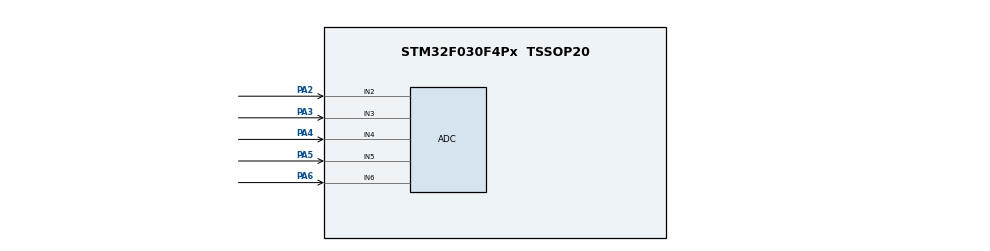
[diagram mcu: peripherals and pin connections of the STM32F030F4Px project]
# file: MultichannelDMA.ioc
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ADC.ClockPrescaler=ADC_CLOCK_SYNC_PCLK_DIV2
ADC.ContinuousConvMode=ENABLE
ADC.DMAContinuousRequests=ENABLE
ADC.Overrun=ADC_OVR_DATA_OVERWRITTEN
ADC.SamplingTime=ADC_SAMPLETIME_71CYCLES_5
Dma.ADC.0.Direction=DMA_PERIPH_TO_MEMORY
Dma.ADC.0.Instance=DMA1_Channel1
Dma.ADC.0.MemDataAlignment=DMA_MDATAALIGN_WORD
Dma.ADC.0.MemInc=DMA_MINC_ENABLE
Dma.ADC.0.Mode=DMA_CIRCULAR
Dma.ADC.0.PeriphDataAlignment=DMA_PDATAALIGN_WORD
Dma.ADC.0.PeriphInc=DMA_PINC_DISABLE
Dma.ADC.0.Priority=DMA_PRIORITY_LOW
Dma.Request0=ADC
Mcu.Family=STM32F0
Mcu.Name=STM32F030F4Px
Mcu.Package=TSSOP20
NVIC.ADC1_IRQn=true\:0\:0\:false\:false\:true\:true\:true
NVIC.DMA1_Channel1_IRQn=true\:0\:0\:false\:false\:true\:false\:true
PA2.Mode=IN2
PA2.Signal=ADC_IN2
PA3.Mode=IN3
PA3.Signal=ADC_IN3
PA4.Mode=IN4
PA4.Signal=ADC_IN4
PA5.Mode=IN5
PA5.Signal=ADC_IN5
PA6.Mode=IN6
PA6.Signal=ADC_IN6
ProjectManager.HeapSize=0x200
ProjectManager.StackSize=0x400
ProjectManager.TargetToolchain=SW4STM32
board=custom

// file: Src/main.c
/* USER CODE BEGIN Header */
/**
  ******************************************************************************
  * @file           : main.c
  * @brief          : Main program body
  ******************************************************************************
  * @attention
  *
  * <h2><center>&copy; Copyright (c) 2019 STMicroelectronics.
  * All rights reserved.</center></h2>
  *
  * This software component is licensed by ST under BSD 3-Clause license,
  * the "License"; You may not use this file except in compliance with the
  * License. You may obtain a copy of the License at:
  *                        opensource.org/licenses/BSD-3-Clause
  *
  ******************************************************************************
  */
/* USER CODE END Header */

#include "main.h"

ADC_HandleTypeDef hadc;
DMA_HandleTypeDef hdma_adc;

/* USER CODE BEGIN PV */
int data[5];
/* USER CODE END PV */

void SystemClock_Config(void);
static void MX_GPIO_Init(void);
static void MX_DMA_Init(void);
static void MX_ADC_Init(void);

int main(void)
{

  /* MCU Configuration--------------------------------------------------------*/

  /* Reset of all peripherals, Initializes the Flash interface and the Systick. */
  HAL_Init();

  /* Configure the system clock */
  SystemClock_Config();

  /* Initialize all configured peripherals */
  MX_GPIO_Init();
  MX_DMA_Init();
  MX_ADC_Init();
  /* USER CODE BEGIN 2 */

  if(HAL_ADCEx_Calibration_Start(&hadc) != HAL_OK){
	  Error_Handler();
  }

  if(HAL_ADC_Start_DMA(&hadc, data, 5) != HAL_OK){
	  Error_Handler();
  }

  /* USER CODE END 2 */

  /* Infinite loop */
  /* USER CODE BEGIN WHILE */
  while (1)
  {

	  HAL_Delay(1);
    /* USER CODE END WHILE */

  }
}

void SystemClock_Config(void)
{
  RCC_OscInitTypeDef RCC_OscInitStruct = {0};
  RCC_ClkInitTypeDef RCC_ClkInitStruct = {0};

  /** Initializes the CPU, AHB and APB busses clocks
  */
  RCC_OscInitStruct.OscillatorType = RCC_OSCILLATORTYPE_HSI;
  RCC_OscInitStruct.HSIState = RCC_HSI_ON;
  RCC_OscInitStruct.HSICalibrationValue = RCC_HSICALIBRATION_DEFAULT;
  RCC_OscInitStruct.PLL.PLLState = RCC_PLL_NONE;
  if (HAL_RCC_OscConfig(&RCC_OscInitStruct) != HAL_OK)
  {
    Error_Handler();
  }
  /** Initializes the CPU, AHB and APB busses clocks
  */
  RCC_ClkInitStruct.ClockType = RCC_CLOCKTYPE_HCLK|RCC_CLOCKTYPE_SYSCLK
                              |RCC_CLOCKTYPE_PCLK1;
  RCC_ClkInitStruct.SYSCLKSource = RCC_SYSCLKSOURCE_HSI;
  RCC_ClkInitStruct.AHBCLKDivider = RCC_SYSCLK_DIV1;
  RCC_ClkInitStruct.APB1CLKDivider = RCC_HCLK_DIV1;

  if (HAL_RCC_ClockConfig(&RCC_ClkInitStruct, FLASH_LATENCY_0) != HAL_OK)
  {
    Error_Handler();
  }
}

static void MX_ADC_Init(void)
{

  ADC_ChannelConfTypeDef sConfig = {0};

  /** Configure the global features of the ADC (Clock, Resolution, Data Alignment and number of conversion)
  */
  hadc.Instance = ADC1;
  hadc.Init.ClockPrescaler = ADC_CLOCK_SYNC_PCLK_DIV2;
  hadc.Init.Resolution = ADC_RESOLUTION_12B;
  hadc.Init.DataAlign = ADC_DATAALIGN_RIGHT;
  hadc.Init.ScanConvMode = ADC_SCAN_DIRECTION_FORWARD;
  hadc.Init.EOCSelection = ADC_EOC_SINGLE_CONV;
  hadc.Init.LowPowerAutoWait = DISABLE;
  hadc.Init.LowPowerAutoPowerOff = DISABLE;
  hadc.Init.ContinuousConvMode = ENABLE;
  hadc.Init.DiscontinuousConvMode = DISABLE;
  hadc.Init.ExternalTrigConv = ADC_SOFTWARE_START;
  hadc.Init.ExternalTrigConvEdge = ADC_EXTERNALTRIGCONVEDGE_NONE;
  hadc.Init.DMAContinuousRequests = ENABLE;
  hadc.Init.Overrun = ADC_OVR_DATA_OVERWRITTEN;
  if (HAL_ADC_Init(&hadc) != HAL_OK)
  {
    Error_Handler();
  }
  /** Configure for the selected ADC regular channel to be converted.
  */
  sConfig.Channel = ADC_CHANNEL_2;
  sConfig.Rank = ADC_RANK_CHANNEL_NUMBER;
  sConfig.SamplingTime = ADC_SAMPLETIME_71CYCLES_5;
  if (HAL_ADC_ConfigChannel(&hadc, &sConfig) != HAL_OK)
  {
    Error_Handler();
  }
  /** Configure for the selected ADC regular channel to be converted.
  */
  sConfig.Channel = ADC_CHANNEL_3;
  if (HAL_ADC_ConfigChannel(&hadc, &sConfig) != HAL_OK)
  {
    Error_Handler();
  }
  /** Configure for the selected ADC regular channel to be converted.
  */
  sConfig.Channel = ADC_CHANNEL_4;
  if (HAL_ADC_ConfigChannel(&hadc, &sConfig) != HAL_OK)
  {
    Error_Handler();
  }
  /** Configure for the selected ADC regular channel to be converted.
  */
  sConfig.Channel = ADC_CHANNEL_5;
  if (HAL_ADC_ConfigChannel(&hadc, &sConfig) != HAL_OK)
  {
    Error_Handler();
  }
  /** Configure for the selected ADC regular channel to be converted.
  */
  sConfig.Channel = ADC_CHANNEL_6;
  if (HAL_ADC_ConfigChannel(&hadc, &sConfig) != HAL_OK)
  {
    Error_Handler();
  }

}

static void MX_DMA_Init(void)
{

  /* DMA controller clock enable */
  __HAL_RCC_DMA1_CLK_ENABLE();

  /* DMA interrupt init */
  /* DMA1_Channel1_IRQn interrupt configuration */
  HAL_NVIC_SetPriority(DMA1_Channel1_IRQn, 0, 0);
  HAL_NVIC_EnableIRQ(DMA1_Channel1_IRQn);

}

static void MX_GPIO_Init(void)
{

  /* GPIO Ports Clock Enable */
  __HAL_RCC_GPIOA_CLK_ENABLE();

}

void Error_Handler(void)
{
}

/************************ (C) COPYRIGHT STMicroelectronics *****END OF FILE****/
